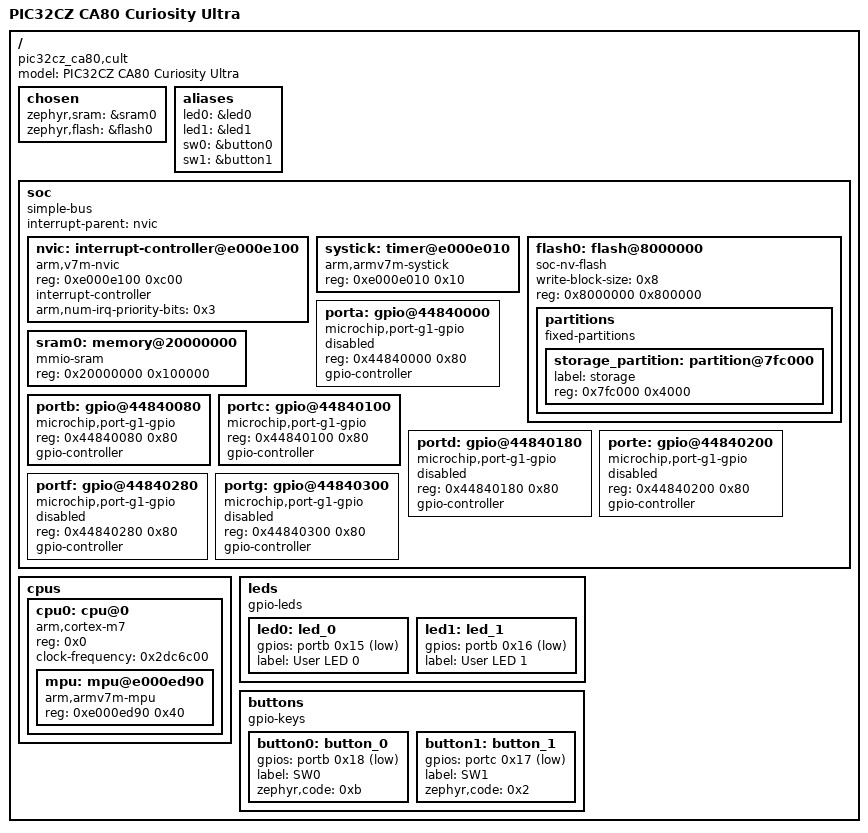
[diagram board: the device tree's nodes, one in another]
/dts-v1/;

/* node '/' defined in zephyr/dts/common/skeleton.dtsi:9 */
/ {
	#address-cells = < 0x1 >;                    /* in zephyr/dts/common/skeleton.dtsi:10 */
	#size-cells = < 0x1 >;                       /* in zephyr/dts/common/skeleton.dtsi:11 */
	model = "PIC32CZ CA80 Curiosity Ultra";      /* in zephyr/boards/microchip/pic32c/pic32cz_ca80_cult/pic32cz_ca80_cult.dts:12 */
	compatible = "pic32cz_ca80,cult",
	             "microchip,pic32cz8110ca80208",
	             "microchip,pic32cz";            /* in zephyr/boards/microchip/pic32c/pic32cz_ca80_cult/pic32cz_ca80_cult.dts:13 */

	/* node '/chosen' defined in zephyr/dts/common/skeleton.dtsi:13 */
	chosen {
		zephyr,sram = &sram0;   /* in zephyr/boards/microchip/pic32c/pic32cz_ca80_cult/pic32cz_ca80_cult.dts:16 */
		zephyr,flash = &flash0; /* in zephyr/boards/microchip/pic32c/pic32cz_ca80_cult/pic32cz_ca80_cult.dts:17 */
	};

	/* node '/aliases' defined in zephyr/dts/common/skeleton.dtsi:15 */
	aliases {
		led0 = &led0;   /* in zephyr/boards/microchip/pic32c/pic32cz_ca80_cult/pic32cz_ca80_cult.dts:21 */
		led1 = &led1;   /* in zephyr/boards/microchip/pic32c/pic32cz_ca80_cult/pic32cz_ca80_cult.dts:22 */
		sw0 = &button0; /* in zephyr/boards/microchip/pic32c/pic32cz_ca80_cult/pic32cz_ca80_cult.dts:23 */
		sw1 = &button1; /* in zephyr/boards/microchip/pic32c/pic32cz_ca80_cult/pic32cz_ca80_cult.dts:24 */
	};

	/* node '/soc' defined in zephyr/dts/arm/armv7-m.dtsi:6 */
	soc {
		#address-cells = < 0x1 >;     /* in zephyr/dts/arm/armv7-m.dtsi:7 */
		#size-cells = < 0x1 >;        /* in zephyr/dts/arm/armv7-m.dtsi:8 */
		compatible = "simple-bus";    /* in zephyr/dts/arm/armv7-m.dtsi:9 */
		interrupt-parent = < &nvic >; /* in zephyr/dts/arm/armv7-m.dtsi:10 */
		ranges;                       /* in zephyr/dts/arm/armv7-m.dtsi:11 */

		/* node '/soc/interrupt-controller@e000e100' defined in zephyr/dts/arm/armv7-m.dtsi:13 */
		nvic: interrupt-controller@e000e100 {
			#address-cells = < 0x1 >;            /* in zephyr/dts/arm/armv7-m.dtsi:14 */
			compatible = "arm,v7m-nvic";         /* in zephyr/dts/arm/armv7-m.dtsi:15 */
			reg = < 0xe000e100 0xc00 >;          /* in zephyr/dts/arm/armv7-m.dtsi:16 */
			interrupt-controller;                /* in zephyr/dts/arm/armv7-m.dtsi:17 */
			#interrupt-cells = < 0x2 >;          /* in zephyr/dts/arm/armv7-m.dtsi:18 */
			arm,num-irq-priority-bits = < 0x3 >; /* in zephyr/dts/arm/microchip/pic32c/pic32cz_ca/common/pic32cz_ca.dtsi:78 */
			phandle = < 0x1 >;                   /* in zephyr/dts/arm/armv7-m.dtsi:10 */
		};

		/* node '/soc/timer@e000e010' defined in zephyr/dts/arm/armv7-m.dtsi:21 */
		systick: timer@e000e010 {
			compatible = "arm,armv7m-systick"; /* in zephyr/dts/arm/armv7-m.dtsi:22 */
			reg = < 0xe000e010 0x10 >;         /* in zephyr/dts/arm/armv7-m.dtsi:23 */
		};

		/* node '/soc/flash@8000000' defined in zephyr/dts/arm/microchip/pic32c/pic32cz_ca/common/pic32cz_ca.dtsi:30 */
		flash0: flash@8000000 {
			compatible = "soc-nv-flash";  /* in zephyr/dts/arm/microchip/pic32c/pic32cz_ca/common/pic32cz_ca.dtsi:31 */
			write-block-size = < 0x8 >;   /* in zephyr/dts/arm/microchip/pic32c/pic32cz_ca/common/pic32cz_ca.dtsi:32 */
			reg = < 0x8000000 0x800000 >; /* in zephyr/dts/arm/microchip/pic32c/pic32cz_ca/common/pic32cz_8110_ca.dtsi:10 */

			/* node '/soc/flash@8000000/partitions' defined in zephyr/boards/microchip/pic32c/pic32cz_ca80_cult/pic32cz_ca80_cult.dts:59 */
			partitions {
				compatible = "fixed-partitions"; /* in zephyr/boards/microchip/pic32c/pic32cz_ca80_cult/pic32cz_ca80_cult.dts:60 */
				#address-cells = < 0x1 >;        /* in zephyr/boards/microchip/pic32c/pic32cz_ca80_cult/pic32cz_ca80_cult.dts:61 */
				#size-cells = < 0x1 >;           /* in zephyr/boards/microchip/pic32c/pic32cz_ca80_cult/pic32cz_ca80_cult.dts:62 */

				/* node '/soc/flash@8000000/partitions/partition@7fc000' defined in zephyr/boards/microchip/pic32c/pic32cz_ca80_cult/pic32cz_ca80_cult.dts:64 */
				storage_partition: partition@7fc000 {
					label = "storage";         /* in zephyr/boards/microchip/pic32c/pic32cz_ca80_cult/pic32cz_ca80_cult.dts:65 */
					reg = < 0x7fc000 0x4000 >; /* in zephyr/boards/microchip/pic32c/pic32cz_ca80_cult/pic32cz_ca80_cult.dts:66 */
				};
			};
		};

		/* node '/soc/memory@20000000' defined in zephyr/dts/arm/microchip/pic32c/pic32cz_ca/common/pic32cz_ca.dtsi:35 */
		sram0: memory@20000000 {
			compatible = "mmio-sram";      /* in zephyr/dts/arm/microchip/pic32c/pic32cz_ca/common/pic32cz_ca.dtsi:36 */
			reg = < 0x20000000 0x100000 >; /* in zephyr/dts/arm/microchip/pic32c/pic32cz_ca/common/pic32cz_8110_ca.dtsi:14 */
		};

		/* node '/soc/gpio@44840000' defined in zephyr/dts/arm/microchip/pic32c/pic32cz_ca/common/pic32cz_ca.dtsi:39 */
		porta: gpio@44840000 {
			status = "disabled";                   /* in zephyr/dts/arm/microchip/pic32c/pic32cz_ca/common/pic32cz_ca.dtsi:40 */
			compatible = "microchip,port-g1-gpio"; /* in zephyr/dts/arm/microchip/pic32c/pic32cz_ca/common/pic32cz_ca.dtsi:41 */
			reg = < 0x44840000 0x80 >;             /* in zephyr/dts/arm/microchip/pic32c/pic32cz_ca/common/pic32cz_ca.dtsi:42 */
			gpio-controller;                       /* in zephyr/dts/arm/microchip/pic32c/pic32cz_ca/common/pic32cz_ca.dtsi:43 */
			#gpio-cells = < 0x2 >;                 /* in zephyr/dts/arm/microchip/pic32c/pic32cz_ca/common/pic32cz_ca.dtsi:44 */
			#microchip,pin-cells = < 0x2 >;        /* in zephyr/dts/arm/microchip/pic32c/pic32cz_ca/common/pic32cz_ca.dtsi:45 */
		};

		/* node '/soc/gpio@44840080' defined in zephyr/dts/arm/microchip/pic32c/pic32cz_ca/common/pic32cz_ca.dtsi:48 */
		portb: gpio@44840080 {
			compatible = "microchip,port-g1-gpio"; /* in zephyr/dts/arm/microchip/pic32c/pic32cz_ca/common/pic32cz_ca.dtsi:50 */
			reg = < 0x44840080 0x80 >;             /* in zephyr/dts/arm/microchip/pic32c/pic32cz_ca/common/pic32cz_ca.dtsi:51 */
			gpio-controller;                       /* in zephyr/dts/arm/microchip/pic32c/pic32cz_ca/common/pic32cz_ca.dtsi:52 */
			#gpio-cells = < 0x2 >;                 /* in zephyr/dts/arm/microchip/pic32c/pic32cz_ca/common/pic32cz_ca.dtsi:53 */
			#microchip,pin-cells = < 0x2 >;        /* in zephyr/dts/arm/microchip/pic32c/pic32cz_ca/common/pic32cz_ca.dtsi:54 */
			status = "okay";                       /* in zephyr/boards/microchip/pic32c/pic32cz_ca80_cult/pic32cz_ca80_cult.dts:76 */
			phandle = < 0x2 >;                     /* in zephyr/boards/microchip/pic32c/pic32cz_ca80_cult/pic32cz_ca80_cult.dts:31 */
		};

		/* node '/soc/gpio@44840100' defined in zephyr/dts/arm/microchip/pic32c/pic32cz_ca/common/pic32cz_ca.dtsi:57 */
		portc: gpio@44840100 {
			compatible = "microchip,port-g1-gpio"; /* in zephyr/dts/arm/microchip/pic32c/pic32cz_ca/common/pic32cz_ca.dtsi:59 */
			reg = < 0x44840100 0x80 >;             /* in zephyr/dts/arm/microchip/pic32c/pic32cz_ca/common/pic32cz_ca.dtsi:60 */
			gpio-controller;                       /* in zephyr/dts/arm/microchip/pic32c/pic32cz_ca/common/pic32cz_ca.dtsi:61 */
			#gpio-cells = < 0x2 >;                 /* in zephyr/dts/arm/microchip/pic32c/pic32cz_ca/common/pic32cz_ca.dtsi:62 */
			#microchip,pin-cells = < 0x2 >;        /* in zephyr/dts/arm/microchip/pic32c/pic32cz_ca/common/pic32cz_ca.dtsi:63 */
			status = "okay";                       /* in zephyr/boards/microchip/pic32c/pic32cz_ca80_cult/pic32cz_ca80_cult.dts:80 */
			phandle = < 0x3 >;                     /* in zephyr/boards/microchip/pic32c/pic32cz_ca80_cult/pic32cz_ca80_cult.dts:51 */
		};

		/* node '/soc/gpio@44840180' defined in zephyr/dts/arm/microchip/pic32c/pic32cz_ca/common/pic32cz_ca.dtsi:66 */
		portd: gpio@44840180 {
			status = "disabled";                   /* in zephyr/dts/arm/microchip/pic32c/pic32cz_ca/common/pic32cz_ca.dtsi:67 */
			compatible = "microchip,port-g1-gpio"; /* in zephyr/dts/arm/microchip/pic32c/pic32cz_ca/common/pic32cz_ca.dtsi:68 */
			reg = < 0x44840180 0x80 >;             /* in zephyr/dts/arm/microchip/pic32c/pic32cz_ca/common/pic32cz_ca.dtsi:69 */
			gpio-controller;                       /* in zephyr/dts/arm/microchip/pic32c/pic32cz_ca/common/pic32cz_ca.dtsi:70 */
			#gpio-cells = < 0x2 >;                 /* in zephyr/dts/arm/microchip/pic32c/pic32cz_ca/common/pic32cz_ca.dtsi:71 */
			#microchip,pin-cells = < 0x2 >;        /* in zephyr/dts/arm/microchip/pic32c/pic32cz_ca/common/pic32cz_ca.dtsi:72 */
		};

		/* node '/soc/gpio@44840200' defined in zephyr/dts/arm/microchip/pic32c/pic32cz_ca/common/pic32cz_ca_208.dtsi:11 */
		porte: gpio@44840200 {
			status = "disabled";                   /* in zephyr/dts/arm/microchip/pic32c/pic32cz_ca/common/pic32cz_ca_208.dtsi:12 */
			compatible = "microchip,port-g1-gpio"; /* in zephyr/dts/arm/microchip/pic32c/pic32cz_ca/common/pic32cz_ca_208.dtsi:13 */
			reg = < 0x44840200 0x80 >;             /* in zephyr/dts/arm/microchip/pic32c/pic32cz_ca/common/pic32cz_ca_208.dtsi:14 */
			gpio-controller;                       /* in zephyr/dts/arm/microchip/pic32c/pic32cz_ca/common/pic32cz_ca_208.dtsi:15 */
			#gpio-cells = < 0x2 >;                 /* in zephyr/dts/arm/microchip/pic32c/pic32cz_ca/common/pic32cz_ca_208.dtsi:16 */
			#microchip,pin-cells = < 0x2 >;        /* in zephyr/dts/arm/microchip/pic32c/pic32cz_ca/common/pic32cz_ca_208.dtsi:17 */
		};

		/* node '/soc/gpio@44840280' defined in zephyr/dts/arm/microchip/pic32c/pic32cz_ca/common/pic32cz_ca_208.dtsi:20 */
		portf: gpio@44840280 {
			status = "disabled";                   /* in zephyr/dts/arm/microchip/pic32c/pic32cz_ca/common/pic32cz_ca_208.dtsi:21 */
			compatible = "microchip,port-g1-gpio"; /* in zephyr/dts/arm/microchip/pic32c/pic32cz_ca/common/pic32cz_ca_208.dtsi:22 */
			reg = < 0x44840280 0x80 >;             /* in zephyr/dts/arm/microchip/pic32c/pic32cz_ca/common/pic32cz_ca_208.dtsi:23 */
			gpio-controller;                       /* in zephyr/dts/arm/microchip/pic32c/pic32cz_ca/common/pic32cz_ca_208.dtsi:24 */
			#gpio-cells = < 0x2 >;                 /* in zephyr/dts/arm/microchip/pic32c/pic32cz_ca/common/pic32cz_ca_208.dtsi:25 */
			#microchip,pin-cells = < 0x2 >;        /* in zephyr/dts/arm/microchip/pic32c/pic32cz_ca/common/pic32cz_ca_208.dtsi:26 */
		};

		/* node '/soc/gpio@44840300' defined in zephyr/dts/arm/microchip/pic32c/pic32cz_ca/common/pic32cz_ca_208.dtsi:29 */
		portg: gpio@44840300 {
			status = "disabled";                   /* in zephyr/dts/arm/microchip/pic32c/pic32cz_ca/common/pic32cz_ca_208.dtsi:30 */
			compatible = "microchip,port-g1-gpio"; /* in zephyr/dts/arm/microchip/pic32c/pic32cz_ca/common/pic32cz_ca_208.dtsi:31 */
			reg = < 0x44840300 0x80 >;             /* in zephyr/dts/arm/microchip/pic32c/pic32cz_ca/common/pic32cz_ca_208.dtsi:32 */
			gpio-controller;                       /* in zephyr/dts/arm/microchip/pic32c/pic32cz_ca/common/pic32cz_ca_208.dtsi:33 */
			#gpio-cells = < 0x2 >;                 /* in zephyr/dts/arm/microchip/pic32c/pic32cz_ca/common/pic32cz_ca_208.dtsi:34 */
			#microchip,pin-cells = < 0x2 >;        /* in zephyr/dts/arm/microchip/pic32c/pic32cz_ca/common/pic32cz_ca_208.dtsi:35 */
		};
	};

	/* node '/cpus' defined in zephyr/dts/arm/microchip/pic32c/pic32cz_ca/common/pic32cz_ca.dtsi:11 */
	cpus {
		#address-cells = < 0x1 >; /* in zephyr/dts/arm/microchip/pic32c/pic32cz_ca/common/pic32cz_ca.dtsi:12 */
		#size-cells = < 0x0 >;    /* in zephyr/dts/arm/microchip/pic32c/pic32cz_ca/common/pic32cz_ca.dtsi:13 */

		/* node '/cpus/cpu@0' defined in zephyr/dts/arm/microchip/pic32c/pic32cz_ca/common/pic32cz_ca.dtsi:15 */
		cpu0: cpu@0 {
			device_type = "cpu";             /* in zephyr/dts/arm/microchip/pic32c/pic32cz_ca/common/pic32cz_ca.dtsi:16 */
			compatible = "arm,cortex-m7";    /* in zephyr/dts/arm/microchip/pic32c/pic32cz_ca/common/pic32cz_ca.dtsi:17 */
			reg = < 0x0 >;                   /* in zephyr/dts/arm/microchip/pic32c/pic32cz_ca/common/pic32cz_ca.dtsi:18 */
			#address-cells = < 0x1 >;        /* in zephyr/dts/arm/microchip/pic32c/pic32cz_ca/common/pic32cz_ca.dtsi:19 */
			#size-cells = < 0x1 >;           /* in zephyr/dts/arm/microchip/pic32c/pic32cz_ca/common/pic32cz_ca.dtsi:20 */
			clock-frequency = < 0x2dc6c00 >; /* in zephyr/boards/microchip/pic32c/pic32cz_ca80_cult/pic32cz_ca80_cult.dts:72 */

			/* node '/cpus/cpu@0/mpu@e000ed90' defined in zephyr/dts/arm/microchip/pic32c/pic32cz_ca/common/pic32cz_ca.dtsi:22 */
			mpu: mpu@e000ed90 {
				compatible = "arm,armv7m-mpu"; /* in zephyr/dts/arm/microchip/pic32c/pic32cz_ca/common/pic32cz_ca.dtsi:23 */
				reg = < 0xe000ed90 0x40 >;     /* in zephyr/dts/arm/microchip/pic32c/pic32cz_ca/common/pic32cz_ca.dtsi:24 */
			};
		};
	};

	/* node '/leds' defined in zephyr/boards/microchip/pic32c/pic32cz_ca80_cult/pic32cz_ca80_cult.dts:27 */
	leds {
		compatible = "gpio-leds"; /* in zephyr/boards/microchip/pic32c/pic32cz_ca80_cult/pic32cz_ca80_cult.dts:28 */

		/* node '/leds/led_0' defined in zephyr/boards/microchip/pic32c/pic32cz_ca80_cult/pic32cz_ca80_cult.dts:30 */
		led0: led_0 {
			gpios = < &portb 0x15 0x1 >; /* in zephyr/boards/microchip/pic32c/pic32cz_ca80_cult/pic32cz_ca80_cult.dts:31 */
			label = "User LED 0";        /* in zephyr/boards/microchip/pic32c/pic32cz_ca80_cult/pic32cz_ca80_cult.dts:32 */
		};

		/* node '/leds/led_1' defined in zephyr/boards/microchip/pic32c/pic32cz_ca80_cult/pic32cz_ca80_cult.dts:35 */
		led1: led_1 {
			gpios = < &portb 0x16 0x1 >; /* in zephyr/boards/microchip/pic32c/pic32cz_ca80_cult/pic32cz_ca80_cult.dts:36 */
			label = "User LED 1";        /* in zephyr/boards/microchip/pic32c/pic32cz_ca80_cult/pic32cz_ca80_cult.dts:37 */
		};
	};

	/* node '/buttons' defined in zephyr/boards/microchip/pic32c/pic32cz_ca80_cult/pic32cz_ca80_cult.dts:41 */
	buttons {
		compatible = "gpio-keys"; /* in zephyr/boards/microchip/pic32c/pic32cz_ca80_cult/pic32cz_ca80_cult.dts:42 */

		/* node '/buttons/button_0' defined in zephyr/boards/microchip/pic32c/pic32cz_ca80_cult/pic32cz_ca80_cult.dts:44 */
		button0: button_0 {
			gpios = < &portb 0x18 0x11 >; /* in zephyr/boards/microchip/pic32c/pic32cz_ca80_cult/pic32cz_ca80_cult.dts:45 */
			label = "SW0";                /* in zephyr/boards/microchip/pic32c/pic32cz_ca80_cult/pic32cz_ca80_cult.dts:46 */
			zephyr,code = < 0xb >;        /* in zephyr/boards/microchip/pic32c/pic32cz_ca80_cult/pic32cz_ca80_cult.dts:47 */
		};

		/* node '/buttons/button_1' defined in zephyr/boards/microchip/pic32c/pic32cz_ca80_cult/pic32cz_ca80_cult.dts:50 */
		button1: button_1 {
			gpios = < &portc 0x17 0x11 >; /* in zephyr/boards/microchip/pic32c/pic32cz_ca80_cult/pic32cz_ca80_cult.dts:51 */
			label = "SW1";                /* in zephyr/boards/microchip/pic32c/pic32cz_ca80_cult/pic32cz_ca80_cult.dts:52 */
			zephyr,code = < 0x2 >;        /* in zephyr/boards/microchip/pic32c/pic32cz_ca80_cult/pic32cz_ca80_cult.dts:53 */
		};
	};
};
